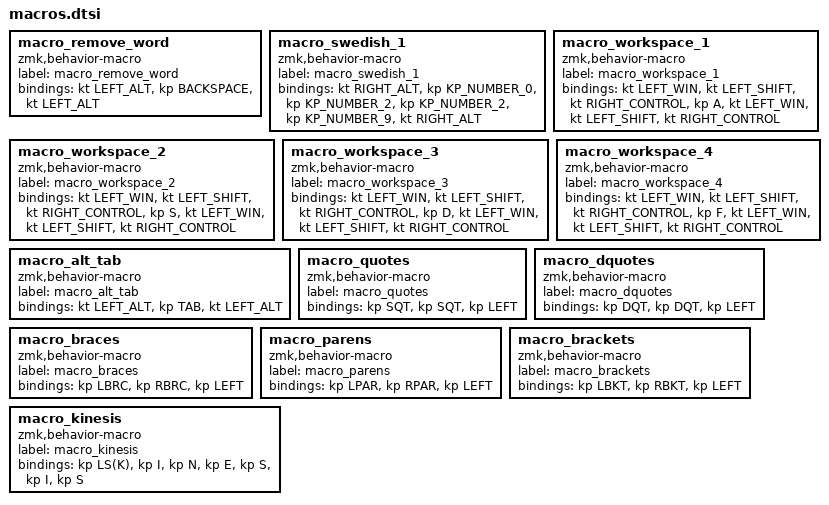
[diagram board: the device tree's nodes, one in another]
macro_remove_word: macro_remove_word{
compatible = "zmk,behavior-macro";
label = "macro_remove_word";
#binding-cells = <0>;
bindings = <&kt LEFT_ALT>, <&kp BACKSPACE>, <&kt LEFT_ALT>;
};
macro_swedish_1: macro_swedish_1{
compatible = "zmk,behavior-macro";
label = "macro_swedish_1";
#binding-cells = <0>;
bindings = <&kt RIGHT_ALT>, <&kp KP_NUMBER_0>, <&kp KP_NUMBER_2>, <&kp KP_NUMBER_2>, <&kp KP_NUMBER_9>, <&kt RIGHT_ALT>;
};
macro_workspace_1: macro_workspace_1{
compatible = "zmk,behavior-macro";
label = "macro_workspace_1";
#binding-cells = <0>;
bindings = <&kt LEFT_WIN>, <&kt LEFT_SHIFT>, <&kt RIGHT_CONTROL>, <&kp A>, <&kt LEFT_WIN>, <&kt LEFT_SHIFT>, <&kt RIGHT_CONTROL>;
};
macro_workspace_2: macro_workspace_2{
compatible = "zmk,behavior-macro";
label = "macro_workspace_2";
#binding-cells = <0>;
bindings = <&kt LEFT_WIN>, <&kt LEFT_SHIFT>, <&kt RIGHT_CONTROL>, <&kp S>, <&kt LEFT_WIN>, <&kt LEFT_SHIFT>, <&kt RIGHT_CONTROL>;
};
macro_workspace_3: macro_workspace_3{
compatible = "zmk,behavior-macro";
label = "macro_workspace_3";
#binding-cells = <0>;
bindings = <&kt LEFT_WIN>, <&kt LEFT_SHIFT>, <&kt RIGHT_CONTROL>, <&kp D>, <&kt LEFT_WIN>, <&kt LEFT_SHIFT>, <&kt RIGHT_CONTROL>;
};
macro_workspace_4: macro_workspace_4{
compatible = "zmk,behavior-macro";
label = "macro_workspace_4";
#binding-cells = <0>;
bindings = <&kt LEFT_WIN>, <&kt LEFT_SHIFT>, <&kt RIGHT_CONTROL>, <&kp F>, <&kt LEFT_WIN>, <&kt LEFT_SHIFT>, <&kt RIGHT_CONTROL>;
};
macro_alt_tab: macro_alt_tab{
compatible = "zmk,behavior-macro";
label = "macro_alt_tab";
#binding-cells = <0>;
bindings = <&kt LEFT_ALT>, <&kp TAB>, <&kt LEFT_ALT>;
};
macro_quotes: macro_quotes{
compatible = "zmk,behavior-macro";
label = "macro_quotes";
#binding-cells = <0>;
bindings = <&kp SQT>, <&kp SQT>, <&kp LEFT>;
};
macro_dquotes: macro_dquotes{
compatible = "zmk,behavior-macro";
label = "macro_dquotes";
#binding-cells = <0>;
bindings = <&kp DQT>, <&kp DQT>, <&kp LEFT>;
};
macro_braces: macro_braces{
compatible = "zmk,behavior-macro";
label = "macro_braces";
#binding-cells = <0>;
bindings = <&kp LBRC>, <&kp RBRC>, <&kp LEFT>;
};
macro_parens: macro_parens{
compatible = "zmk,behavior-macro";
label = "macro_parens";
#binding-cells = <0>;
bindings = <&kp LPAR>, <&kp RPAR>, <&kp LEFT>;
};
macro_brackets: macro_brackets{
compatible = "zmk,behavior-macro";
label = "macro_brackets";
#binding-cells = <0>;
bindings = <&kp LBKT>, <&kp RBKT>, <&kp LEFT>;
};
macro_kinesis: macro_kinesis{
compatible = "zmk,behavior-macro";
label = "macro_kinesis";
#binding-cells = <0>;
bindings = <&kp LS(K)>, <&kp I>, <&kp N>, <&kp E>, <&kp S>, <&kp I>, <&kp S>;
};
macro_kinesis: macro_kinesis{
compatible = "zmk,behavior-macro";
label = "macro_kinesis";
#binding-cells = <0>;
bindings = <&kp LS(K)>, <&kp I>, <&kp N>, <&kp E>, <&kp S>, <&kp I>, <&kp S>;
};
